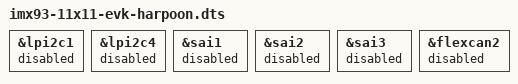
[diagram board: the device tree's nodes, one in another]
// SPDX-License-Identifier: (GPL-2.0+ OR MIT)
/*
 * Copyright 2023 NXP
 */

#include "imx93-11x11-evk-root.dts"
#include "imx93-rpmsg-ca55.dtsi"

&lpi2c1 {
	status = "disabled";
};

&lpi2c4 {
	status = "disabled";
};

&sai1 {
	status = "disabled";
};

&sai2 {
	status = "disabled";
};

&sai3 {
	status = "disabled";
};

&flexcan2 {
	status = "disabled";
};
